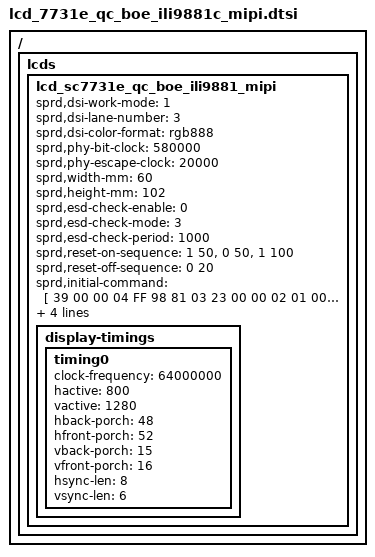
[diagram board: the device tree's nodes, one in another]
/ { lcds {
	lcd_sc7731e_qc_boe_ili9881_mipi: lcd_sc7731e_qc_boe_ili9881_mipi {

		sprd,dsi-work-mode = <1>;
		sprd,dsi-lane-number = <3>;
		sprd,dsi-color-format = "rgb888";

		sprd,phy-bit-clock = <580000>;
		sprd,phy-escape-clock = <20000>;

		sprd,width-mm = <60>;
		sprd,height-mm = <102>;

		sprd,esd-check-enable = <0>;
		sprd,esd-check-mode = <3>;
		sprd,esd-check-period = <1000>;
		/*sprd,esd-check-register = <0x0A>;*/
		/*sprd,esd-check-value = <0x9C>;*/

		sprd,reset-on-sequence = <1 50>, <0 50>, <1 100>;
		sprd,reset-off-sequence = <0 20>;

		sprd,initial-command = [
                 39 00 00 04 FF 98 81 03 
//GIP_1
		 23 00 00 02 01 00 
		 23 00 00 02 02 00 
		 23 00 00 02 03 53 
		 23 00 00 02 04 53 
		 23 00 00 02 05 13 
		 23 00 00 02 06 04 
		 23 00 00 02 07 02 
		 23 00 00 02 08 02 
		 23 00 00 02 09 00 
		 23 00 00 02 0A 00 
		 23 00 00 02 0B 00 
		 23 00 00 02 0C 00 
		 23 00 00 02 0D 00 
		 23 00 00 02 0E 00 
		 23 00 00 02 0F 00 
		 23 00 00 02 10 00 
		 23 00 00 02 11 00 
		 23 00 00 02 12 00 
		 23 00 00 02 13 00 //00
		 23 00 00 02 14 00 
		 23 00 00 02 15 00 
		 23 00 00 02 16 00 
		 23 00 00 02 17 00 
		 23 00 00 02 18 00 
		 23 00 00 02 19 00 
		 23 00 00 02 1A 00 
		 23 00 00 02 1B 00 
		 23 00 00 02 1C 00 
		 23 00 00 02 1D 00 
		 23 00 00 02 1E C0 
		 23 00 00 02 1F 00 
		 23 00 00 02 20 02 
		 23 00 00 02 21 09 
		 23 00 00 02 22 00 
		 23 00 00 02 23 00 
		 23 00 00 02 24 00 
		 23 00 00 02 25 00 
		 23 00 00 02 26 00 
		 23 00 00 02 27 00 
		 23 00 00 02 28 55 
		 23 00 00 02 29 03 
		 23 00 00 02 2A 00 
		 23 00 00 02 2B 00 
		 23 00 00 02 2C 00 
		 23 00 00 02 2D 00 
		 23 00 00 02 2E 00 
		 23 00 00 02 2F 00 
		 23 00 00 02 30 00 
		 23 00 00 02 31 00 
		 23 00 00 02 32 00 
		 23 00 00 02 33 00 
		 23 00 00 02 34 00   // GPWR1/2 non overlap time 2.62us
		 23 00 00 02 35 00 
		 23 00 00 02 36 00 
		 23 00 00 02 37 00 
		 23 00 00 02 38 3C 
		 23 00 00 02 39 00 
		 23 00 00 02 3A 00 
		 23 00 00 02 3B 00 
		 23 00 00 02 3C 00 
		 23 00 00 02 3D 00 
		 23 00 00 02 3E 00 
		 23 00 00 02 3F 00 
		 23 00 00 02 40 00 
		 23 00 00 02 41 00 
		 23 00 00 02 42 00 
		 23 00 00 02 43 00 
		 23 00 00 02 44 00 
		 23 00 00 02 45 00 
 //GIP_2                         
		 23 00 00 02 50 01 
		 23 00 00 02 51 23 
		 23 00 00 02 52 45 
		 23 00 00 02 53 67 
		 23 00 00 02 54 89 
		 23 00 00 02 55 AB 
		 23 00 00 02 56 01 
		 23 00 00 02 57 23 
		 23 00 00 02 58 45 
		 23 00 00 02 59 67 
		 23 00 00 02 5A 89 
		 23 00 00 02 5B AB 
		 23 00 00 02 5C CD 
		 23 00 00 02 5D EF 
//GIP_3                         
		 23 00 00 02 5E 01 
		 23 00 00 02 5F 0A 
		 23 00 00 02 60 02      //FW_CGOUT_L[2] VSSG_ODD
		 23 00 00 02 61 02      //FW_CGOUT_L[3] VSSG_ODD
		 23 00 00 02 62 08      //FW_CGOUT_L[4] STV2_ODD
		 23 00 00 02 63 15      //FW_CGOUT_L[5] VDD2_ODD
		 23 00 00 02 64 14      //FW_CGOUT_L[6] VDD1_ODD
		 23 00 00 02 65 02      //FW_CGOUT_L[7]
		 23 00 00 02 66 11      //FW_CGOUT_L[8] CK11
		 23 00 00 02 67 10   
		 23 00 00 02 68 02 
		 23 00 00 02 69 0F 
		 23 00 00 02 6A 0E 
		 23 00 00 02 6B 02 
		 23 00 00 02 6C 0D 
		 23 00 00 02 6D 0C 
		 23 00 00 02 6E 06 
		 23 00 00 02 6F 02 
		 23 00 00 02 70 02 
		 23 00 00 02 71 02 
		 23 00 00 02 72 02 
		 23 00 00 02 73 02 
		 23 00 00 02 74 02 
		 23 00 00 02 75 0A      //BW_CGOUT_L[1]   RESE_ODD 
		 23 00 00 02 76 02      //BW_CGOUT_L[2]   VSSG_ODD 
		 23 00 00 02 77 02      //BW_CGOUT_L[3]   VSSG_ODD  
		 23 00 00 02 78 06 
		 23 00 00 02 79 15 
		 23 00 00 02 7A 14 
		 23 00 00 02 7B 02 
		 23 00 00 02 7C 10 
		 23 00 00 02 7D 11 
		 23 00 00 02 7E 02 
		 23 00 00 02 7f 0C      //BW_CGOUT_L[11]  CK7
		 23 00 00 02 80 0D      //BW_CGOUT_L[12]  CK5 
		 23 00 00 02 81 02      //BW_CGOUT_L[13]   
		 23 00 00 02 82 0E      //BW_CGOUT_L[14]  CK3 
		 23 00 00 02 83 0F      //BW_CGOUT_L[15]  CK1 
		 23 00 00 02 84 08      //BW_CGOUT_L[16]  STV1_ODD 
		 23 00 00 02 85 02      //BW_CGOUT_L[17]   
		 23 00 00 02 86 02      //BW_CGOUT_L[18]   
		 23 00 00 02 87 02      //BW_CGOUT_L[19]   
		 23 00 00 02 88 02      //BW_CGOUT_L[20]   
		 23 00 00 02 89 02      //BW_CGOUT_L[21]   
		 23 00 00 02 8A 02      //BW_CGOUT_L[22]   
	//Page 4 command;    
			 39 00 00 04 FF 98 81 04 
			 23 00 00 02 00 00  
		//	 23 00 00 02 2F 01     //zice
			// 23 00 00 02 3B C0      // ILI4003D sel
		 23 00 00 02 6C 15 
		 23 00 00 02 6E 20      //VGH 16V   30
		 23 00 00 02 6F 55      //Pump ratio VGH=VSPX4 VGL=VSNX4
		 23 00 00 02 3A 24 
		 23 00 00 02 8D 1F 
		 23 00 00 02 87 BA 
		 23 00 00 02 26 76 
		 23 00 00 02 B2 D1 
		 23 00 00 02 B5 07 
		 23 00 00 02 35 1F 
		 23 00 00 02 88 0B 
		 23 00 00 02 21 30 
// Page 1 command              
		 39 00 00 04 FF 98 81 01 
		 23 00 00 02 22 0A 
		 23 00 00 02 31 09 
		 23 00 00 02 40 33 
		 23 00 00 02 53 37 
		 23 00 00 02 55 88 
		 23 00 00 02 50 95 
		 23 00 00 02 51 95 
		 23 00 00 02 60 30 

		 23 00 00 02 A0 0F         //VP255Gamma P
		 23 00 00 02 A1 17                //VP251
		 23 00 00 02 A2 22                //VP247
		 23 00 00 02 A3 19               //VP243
		 23 00 00 02 A4 15                //VP239
		 23 00 00 02 A5 28                //VP231
		 23 00 00 02 A6 1C                //VP219
		 23 00 00 02 A7 1C                //VP203
		 23 00 00 02 A8 78                //VP175
		 23 00 00 02 A9 1C                //VP144
		 23 00 00 02 AA 28                //VP111
		 23 00 00 02 AB 69                //VP80
		 23 00 00 02 AC 1A                //VP52
		 23 00 00 02 AD 19                //VP36
		 23 00 00 02 AE 4B                //VP24
		 23 00 00 02 AF 22                //VP16
		 23 00 00 02 B0 2A                //VP12
		 23 00 00 02 B1 4B                //VP8
		 23 00 00 02 B2 6B                //VP4
		 23 00 00 02 B3 3F                //VP0

		 23 00 00 02 C0 01          //VN255 GAMMA N
		 23 00 00 02 C1 17                //VN251
		 23 00 00 02 C2 22                //VN247
		 23 00 00 02 C3 19               //VN243
		 23 00 00 02 C4 15                //VN239
		 23 00 00 02 C5 28                //VN231
		 23 00 00 02 C6 1C                //VN219
		 23 00 00 02 C7 1D                //VN203
		 23 00 00 02 C8 78                //VN175
		 23 00 00 02 C9 1C                //VN144
		 23 00 00 02 CA 28                //VN111
		 23 00 00 02 CB 69                //VN80
		 23 00 00 02 CC 1A                //VN52
		 23 00 00 02 CD 19                //VN36
		 23 00 00 02 CE 4B                //VN24
		 23 00 00 02 CF 22                //VN16
		 23 00 00 02 D0 2A                //VN12
		 23 00 00 02 D1 4B                //VN8
		 23 00 00 02 D2 6B                //VN4
			 23 00 00 02 D3 3F         //VN0
			 39 00 00 04 FF 98 81 00 	

			13 78 00 01 11
			13 64 00 01 29
			];
		sprd,sleep-in-command = [
			13 0A 00 01 28
			13 78 00 01 10
			];
		sprd,sleep-out-command = [
			13 78 00 01 11
			13 64 00 01 29
			];

		display-timings {
			timing0 {
			clock-frequency = <64000000>;
			hactive = <800>;
			vactive = <1280>;
			hback-porch = <48>;
			hfront-porch = <52>;
			vback-porch = <15>;
			vfront-porch = <16>;
			hsync-len = <8>;
			vsync-len = <6>;
			};
		};
	};
};};

